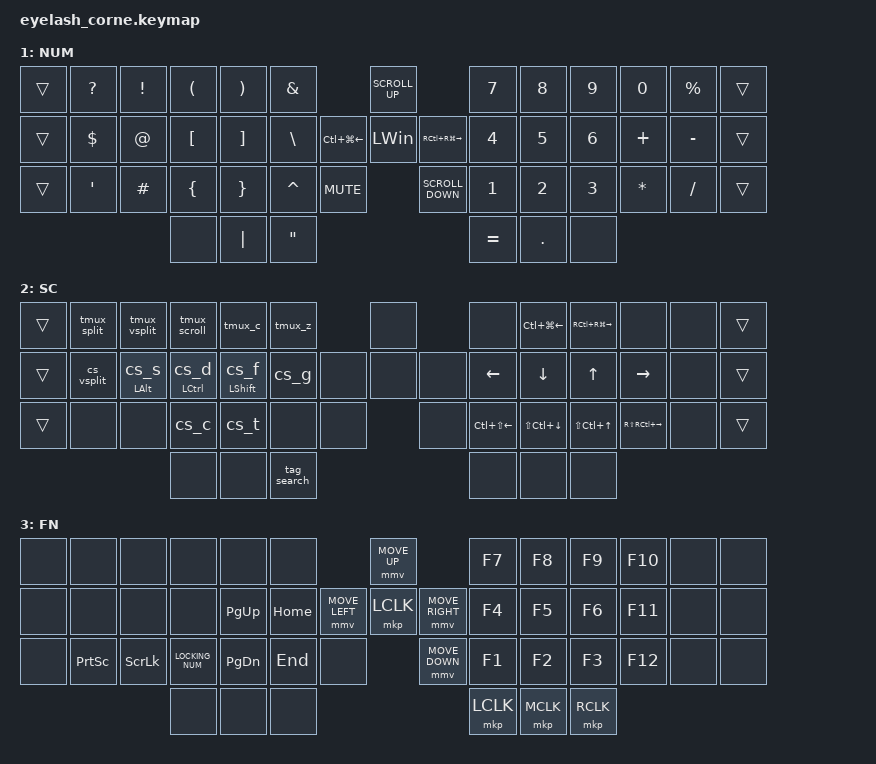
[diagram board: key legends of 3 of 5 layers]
#define ZMK_POINTING_DEFAULT_MOVE_VAL 1200  // 600
#define ZMK_POINTING_DEFAULT_SCRL_VAL 25   // 10
#define MT_TAPPING_TERM_MS 250
#define TD_TAPPING_TERM_MS 200
#define LT_TAPPING_TERM_MS 250
#define TDLT_TD_TAPPING_TERM_MS 185
#define TDLT_TD_TAPPING_TERM_200MS 200
#define TDLT_TD_TAPPING_TERM_175MS 175
#define TDLT_LT_TAPPING_TERM_MS 200
#define TDLT_LT_TAPPING_TERM_225MS 225
#define TDLT_LT_TAPPING_TERM_200MS 200
#define DEFAULT_QUICK_TAP_TERM 200

#include <input/processors.dtsi>
#include <zephyr/dt-bindings/input/input-event-codes.h>
#include <behaviors.dtsi>
#include <dt-bindings/zmk/bt.h>
#include <dt-bindings/zmk/keys.h>
#include <dt-bindings/zmk/pointing.h>
#include <dt-bindings/zmk/rgb.h>

&mmv_input_listener { input-processors = <&zip_xy_scaler 2 1>; };

&msc_input_listener { input-processors = <&zip_scroll_scaler 2 1>; };

&msc {
    acceleration-exponent = <1>;      // 0
    time-to-max-speed-ms = <100>;       // 300
    delay-ms = <0>;                   // 0
};

&led_strip {
    chain-length = <21>; // Or 27 if you have underglow
};

&mmv {
    time-to-max-speed-ms = <500>;
    acceleration-exponent = <1>;
    trigger-period-ms = <16>;
};

&soft_off { hold-time-ms = <2000>; };

/ {
    chosen { zmk,underglow-layer-colors = <&layer_0_color &layer_1_color &layer_2_color &layer_3_color &layer_4_color>; };

    layer_0_color: color_0 {
        color = <0 0 0>; // White for QWERTY Layer
    };

    layer_1_color: color_1 {
        color = <200 100 50>; // Blue for NUM Layer
    };

    layer_2_color: color_2 {
        color = <180 100 50>;   // Cyan for SC Layer
    };

    layer_3_color: color_3 {
        color = <120 100 50>; // Green for FN Layer
    };

    layer_4_color: color_4 {
        color = <0 100 50>; // Red for KBD Layer
    };
};

/ {
    behaviors {
        mt_hp: mt_hp {
            compatible = "zmk,behavior-hold-tap";
            #binding-cells = <2>;
            flavor = "hold-preferred";
            tapping-term-ms = <MT_TAPPING_TERM_MS>;
            quick-tap-ms = <DEFAULT_QUICK_TAP_TERM>;
            bindings = <&kp>, <&kp>;
        };

        mt_tp: mt_tp {
            compatible = "zmk,behavior-hold-tap";
            #binding-cells = <2>;
            flavor = "tap-preferred";
            tapping-term-ms = <MT_TAPPING_TERM_MS>;
            quick-tap-ms = <DEFAULT_QUICK_TAP_TERM>;
            bindings = <&kp>, <&kp>;
        };

        mt_bal: mt_bal {
            compatible = "zmk,behavior-hold-tap";
            #binding-cells = <2>;
            flavor = "balanced";
            tapping-term-ms = <MT_TAPPING_TERM_MS>;
            quick-tap-ms = <DEFAULT_QUICK_TAP_TERM>;
            bindings = <&kp>, <&kp>;
        };

        mt_tui: mt_tui {
            compatible = "zmk,behavior-hold-tap";
            #binding-cells = <2>;
            flavor = "tap-unless-interrupted";
            tapping-term-ms = <MT_TAPPING_TERM_MS>;
            quick-tap-ms = <DEFAULT_QUICK_TAP_TERM>;
            bindings = <&kp>, <&kp>;
        };

        mt_l1_shift_bal: mt_l1_shift_bal {
            compatible = "zmk,behavior-hold-tap";
            #binding-cells = <2>;
            flavor = "balanced";
            tapping-term-ms = <MT_TAPPING_TERM_MS>;
            quick-tap-ms = <DEFAULT_QUICK_TAP_TERM>;
            bindings = <&kp>, <&cs_f>;
        };

        mt_l1_ctrl_bal: mt_l1_ctrl_bal {
            compatible = "zmk,behavior-hold-tap";
            #binding-cells = <2>;
            flavor = "balanced";
            tapping-term-ms = <MT_TAPPING_TERM_MS>;
            quick-tap-ms = <DEFAULT_QUICK_TAP_TERM>;
            bindings = <&kp>, <&cs_d>;
        };

        mt_l1_alt_bal: mt_l1_alt_bal {
            compatible = "zmk,behavior-hold-tap";
            #binding-cells = <2>;
            flavor = "balanced";
            tapping-term-ms = <MT_TAPPING_TERM_MS>;
            quick-tap-ms = <DEFAULT_QUICK_TAP_TERM>;
            bindings = <&kp>, <&cs_s>;
        };

        mt_l1_shift_hp: mt_l1_shift_hp {
            compatible = "zmk,behavior-hold-tap";
            #binding-cells = <2>;
            flavor = "hold-preferred";
            tapping-term-ms = <MT_TAPPING_TERM_MS>;
            quick-tap-ms = <DEFAULT_QUICK_TAP_TERM>;
            bindings = <&kp>, <&cs_f>;
        };

        mt_l1_ctrl_hp: mt_l1_ctrl_hp {
            compatible = "zmk,behavior-hold-tap";
            #binding-cells = <2>;
            flavor = "hold-preferred";
            tapping-term-ms = <MT_TAPPING_TERM_MS>;
            quick-tap-ms = <DEFAULT_QUICK_TAP_TERM>;
            bindings = <&kp>, <&cs_d>;
        };

        mt_l1_alt_hp: mt_l1_alt_hp {
            compatible = "zmk,behavior-hold-tap";
            #binding-cells = <2>;
            flavor = "hold-preferred";
            tapping-term-ms = <MT_TAPPING_TERM_MS>;
            quick-tap-ms = <DEFAULT_QUICK_TAP_TERM>;
            bindings = <&kp>, <&cs_s>;
        };

        mt_l1_shift_tui: mt_l1_shift_tui {
            compatible = "zmk,behavior-hold-tap";
            #binding-cells = <2>;
            flavor = "tap-unless-interrupted";
            tapping-term-ms = <MT_TAPPING_TERM_MS>;
            quick-tap-ms = <DEFAULT_QUICK_TAP_TERM>;
            bindings = <&kp>, <&cs_f>;
        };

        mt_l1_ctrl_tui: mt_l1_ctrl_tui {
            compatible = "zmk,behavior-hold-tap";
            #binding-cells = <2>;
            flavor = "tap-unless-interrupted";
            tapping-term-ms = <MT_TAPPING_TERM_MS>;
            quick-tap-ms = <DEFAULT_QUICK_TAP_TERM>;
            bindings = <&kp>, <&cs_d>;
        };

        mt_l1_alt_tui: mt_l1_alt_tui {
            compatible = "zmk,behavior-hold-tap";
            #binding-cells = <2>;
            flavor = "tap-unless-interrupted";
            tapping-term-ms = <MT_TAPPING_TERM_MS>;
            quick-tap-ms = <DEFAULT_QUICK_TAP_TERM>;
            bindings = <&kp>, <&cs_s>;
        };

        lt_hp: lt_hp {
            compatible = "zmk,behavior-hold-tap";
            #binding-cells = <2>;
            flavor = "hold-preferred";
            tapping-term-ms = <TDLT_LT_TAPPING_TERM_MS>;
            quick-tap-ms = <DEFAULT_QUICK_TAP_TERM>;
            bindings = <&mo>, <&kp>;
        };

        lt_hp_200: lt_hp_200 {
            compatible = "zmk,behavior-hold-tap";
            #binding-cells = <2>;
            flavor = "hold-preferred";
            tapping-term-ms = <TDLT_LT_TAPPING_TERM_200MS>;
            quick-tap-ms = <DEFAULT_QUICK_TAP_TERM>;
            bindings = <&mo>, <&kp>;
        };

        lt_hp_225: lt_hp_225 {
            compatible = "zmk,behavior-hold-tap";
            #binding-cells = <2>;
            flavor = "hold-preferred";
            tapping-term-ms = <TDLT_LT_TAPPING_TERM_225MS>;
            quick-tap-ms = <DEFAULT_QUICK_TAP_TERM>;
            bindings = <&mo>, <&kp>;
        };

        lt_tp: lt_tp {
            compatible = "zmk,behavior-hold-tap";
            #binding-cells = <2>;
            flavor = "tap-preferred";
            tapping-term-ms = <TDLT_LT_TAPPING_TERM_MS>;
            quick-tap-ms = <DEFAULT_QUICK_TAP_TERM>;
            bindings = <&mo>, <&kp>;
        };

        lt_bal: lt_bal {
            compatible = "zmk,behavior-hold-tap";
            #binding-cells = <2>;
            flavor = "balanced";
            tapping-term-ms = <TDLT_LT_TAPPING_TERM_MS>;
            quick-tap-ms = <DEFAULT_QUICK_TAP_TERM>;
            bindings = <&mo>, <&kp>;
        };

        lt_tui: lt_tui {
            compatible = "zmk,behavior-hold-tap";
            #binding-cells = <2>;
            flavor = "tap-unless-interrupted";
            tapping-term-ms = <TDLT_LT_TAPPING_TERM_MS>;
            quick-tap-ms = <DEFAULT_QUICK_TAP_TERM>;
            bindings = <&mo>, <&kp>;
        };

        lt_bal_250_0: lt_bal_250_0 {
            compatible = "zmk,behavior-hold-tap";
            #binding-cells = <2>;
            flavor = "balanced";
            tapping-term-ms = <LT_TAPPING_TERM_MS>;
            quick-tap-ms = <DEFAULT_QUICK_TAP_TERM>;
            bindings = <&mo>, <&kp>;
        };

        lt_bal_250_25: lt_bal_250_25 {
            compatible = "zmk,behavior-hold-tap";
            #binding-cells = <2>;
            flavor = "balanced";
            tapping-term-ms = <LT_TAPPING_TERM_MS>;
            quick-tap-ms = <DEFAULT_QUICK_TAP_TERM>;
            bindings = <&mo>, <&kp>;
        };

        lt_bal_250_25_rgb_L1: lt_bal_250_25_rgb_L1 {
            compatible = "zmk,behavior-hold-tap";
            #binding-cells = <2>;
            flavor = "balanced";
            tapping-term-ms = <LT_TAPPING_TERM_MS>;
            quick-tap-ms = <DEFAULT_QUICK_TAP_TERM>;
            bindings = <&mo_rgb_1>, <&kp>;
        };

        lt_bal_250_25_rgb_L2: lt_bal_250_25_rgb_L2 {
            compatible = "zmk,behavior-hold-tap";
            #binding-cells = <2>;
            flavor = "balanced";
            tapping-term-ms = <LT_TAPPING_TERM_MS>;
            quick-tap-ms = <DEFAULT_QUICK_TAP_TERM>;
            bindings = <&mo_rgb_2>, <&kp>;
        };

        lt_bal_250_25_rgb_L3: lt_bal_250_25_rgb_L3 {
            compatible = "zmk,behavior-hold-tap";
            #binding-cells = <2>;
            flavor = "balanced";
            tapping-term-ms = <LT_TAPPING_TERM_MS>;
            quick-tap-ms = <DEFAULT_QUICK_TAP_TERM>;
            bindings = <&mo_rgb_3>, <&kp>;
        };

        lt_bal_250_25_rgb_L4: lt_bal_250_25_rgb_L4 {
            compatible = "zmk,behavior-hold-tap";
            #binding-cells = <2>;
            flavor = "balanced";
            tapping-term-ms = <LT_TAPPING_TERM_MS>;
            quick-tap-ms = <DEFAULT_QUICK_TAP_TERM>;
            bindings = <&mo_rgb_4>, <&kp>;
        };

        lt_bal_250_50: lt_bal_250_50 {
            compatible = "zmk,behavior-hold-tap";
            #binding-cells = <2>;
            flavor = "balanced";
            tapping-term-ms = <LT_TAPPING_TERM_MS>;
            quick-tap-ms = <DEFAULT_QUICK_TAP_TERM>;
            bindings = <&mo>, <&kp>;
        };

        lt_bal_250_100: lt_bal_250_100 {
            compatible = "zmk,behavior-hold-tap";
            #binding-cells = <2>;
            flavor = "balanced";
            tapping-term-ms = <LT_TAPPING_TERM_MS>;
            quick-tap-ms = <DEFAULT_QUICK_TAP_TERM>;
            bindings = <&mo>, <&kp>;
        };

        lt_tp_250_0: lt_tp_250_0 {
            compatible = "zmk,behavior-hold-tap";
            #binding-cells = <2>;
            flavor = "tap-preferred";
            tapping-term-ms = <LT_TAPPING_TERM_MS>;
            quick-tap-ms = <DEFAULT_QUICK_TAP_TERM>;
            bindings = <&mo>, <&kp>;
        };

        lt_tp_250_50: lt_tp_250_50 {
            compatible = "zmk,behavior-hold-tap";
            #binding-cells = <2>;
            flavor = "tap-preferred";
            tapping-term-ms = <LT_TAPPING_TERM_MS>;
            quick-tap-ms = <DEFAULT_QUICK_TAP_TERM>;
            bindings = <&mo>, <&kp>;
        };

        lt_tui_250_0: lt_tui_250_0 {
            compatible = "zmk,behavior-hold-tap";
            #binding-cells = <2>;
            flavor = "tap-unless-interrupted";
            tapping-term-ms = <LT_TAPPING_TERM_MS>;
            quick-tap-ms = <DEFAULT_QUICK_TAP_TERM>;
            bindings = <&mo>, <&kp>;
        };

        lt_tui_250_50: lt_tui_250_50 {
            compatible = "zmk,behavior-hold-tap";
            #binding-cells = <2>;
            flavor = "tap-unless-interrupted";
            tapping-term-ms = <LT_TAPPING_TERM_MS>;
            quick-tap-ms = <DEFAULT_QUICK_TAP_TERM>;
            bindings = <&mo>, <&kp>;
        };

        td_lt_bal_space_grave_L1: td_lt_bal_space_grave_L1 {
            compatible = "zmk,behavior-tap-dance";
            #binding-cells = <0>;
            tapping-term-ms = <TDLT_TD_TAPPING_TERM_MS>;
            bindings = <&lt_bal 1 SPACE>, <&kp GRAVE>;
        };

        td_lt_bal_enter_esc_L1: td_lt_bal_enter_esc_L1 {
            compatible = "zmk,behavior-tap-dance";
            #binding-cells = <0>;
            tapping-term-ms = <TDLT_TD_TAPPING_TERM_MS>;
            bindings = <&lt_bal 1 RETURN>, <&kp ESC>;
        };

        td_lt_hp_space_grave_L1: td_lt_hp_space_grave_L1 {
            compatible = "zmk,behavior-tap-dance";
            #binding-cells = <0>;
            tapping-term-ms = <TDLT_TD_TAPPING_TERM_MS>;
            bindings = <&lt_hp 1 SPACE>, <&kp GRAVE>;
        };

        td_lt_hp_enter_esc_L1: td_lt_hp_enter_esc_L1 {
            compatible = "zmk,behavior-tap-dance";
            #binding-cells = <0>;
            tapping-term-ms = <TDLT_TD_TAPPING_TERM_MS>;
            bindings = <&lt_hp 1 RETURN>, <&kp ESC>;
        };

        td_200_lt_225_hp_space_grave_L1: td_200_lt_225_hp_space_grave_L1 {
            compatible = "zmk,behavior-tap-dance";
            #binding-cells = <0>;
            tapping-term-ms = <TDLT_TD_TAPPING_TERM_200MS>;
            bindings = <&lt_hp_225 1 SPACE>, <&kp GRAVE>;
        };

        td_200_lt_225_hp_enter_esc_L1: td_200_lt_225_hp_enter_esc_L1 {
            compatible = "zmk,behavior-tap-dance";
            #binding-cells = <0>;
            tapping-term-ms = <TDLT_TD_TAPPING_TERM_200MS>;
            bindings = <&lt_hp_225 1 RETURN>, <&kp ESC>;
        };

        td_200_lt_200_hp_space_grave_L1: td_200_lt_200_hp_space_grave_L1 {
            compatible = "zmk,behavior-tap-dance";
            #binding-cells = <0>;
            tapping-term-ms = <TDLT_TD_TAPPING_TERM_200MS>;
            bindings = <&lt_hp_200 1 SPACE>, <&kp GRAVE>;
        };

        td_200_lt_200_hp_enter_esc_L1: td_200_lt_200_hp_enter_esc_L1 {
            compatible = "zmk,behavior-tap-dance";
            #binding-cells = <0>;
            tapping-term-ms = <TDLT_TD_TAPPING_TERM_200MS>;
            bindings = <&lt_hp_200 1 RETURN>, <&kp ESC>;
        };

        td_175_lt_200_hp_space_grave_L1: td_175_lt_200_hp_space_grave_L1 {
            compatible = "zmk,behavior-tap-dance";
            #binding-cells = <0>;
            tapping-term-ms = <TDLT_TD_TAPPING_TERM_175MS>;
            bindings = <&lt_hp_200 1 SPACE>, <&kp GRAVE>;
        };

        td_175_lt_200_hp_enter_esc_L1: td_175_lt_200_hp_enter_esc_L1 {
            compatible = "zmk,behavior-tap-dance";
            #binding-cells = <0>;
            tapping-term-ms = <TDLT_TD_TAPPING_TERM_175MS>;
            bindings = <&lt_hp_200 1 RETURN>, <&kp ESC>;
        };

        td_lt_tp_space_grave_L1: td_lt_tp_space_grave_L1 {
            compatible = "zmk,behavior-tap-dance";
            #binding-cells = <0>;
            tapping-term-ms = <TDLT_TD_TAPPING_TERM_MS>;
            bindings = <&lt_tp 1 SPACE>, <&kp GRAVE>;
        };

        td_lt_tp_enter_esc_L1: td_lt_tp_enter_esc_L1 {
            compatible = "zmk,behavior-tap-dance";
            #binding-cells = <0>;
            tapping-term-ms = <TDLT_TD_TAPPING_TERM_MS>;
            bindings = <&lt_tp 1 RETURN>, <&kp ESC>;
        };

        td_lt_tui_space_grave_L1: td_lt_tui_space_grave_L1 {
            compatible = "zmk,behavior-tap-dance";
            #binding-cells = <0>;
            tapping-term-ms = <TDLT_TD_TAPPING_TERM_MS>;
            bindings = <&lt_tui 1 SPACE>, <&kp GRAVE>;
        };

        td_lt_tui_enter_esc_L1: td_lt_tui_enter_esc_L1 {
            compatible = "zmk,behavior-tap-dance";
            #binding-cells = <0>;
            tapping-term-ms = <TDLT_TD_TAPPING_TERM_MS>;
            bindings = <&lt_tui 1 RETURN>, <&kp ESC>;
        };

        td_comma_underscore: td_comma_underscore {
            compatible = "zmk,behavior-tap-dance";
            #binding-cells = <0>;
            tapping-term-ms = <TD_TAPPING_TERM_MS>;
            bindings = <&kp COMMA>, <&kp LS(MINUS)>;
        };
    };

    rgb_encoder: rgb_encoder {
        compatible = "zmk,behavior-sensor-rotate";
        #sensor-binding-cells = <0>;
        bindings = <&rgb_ug RGB_BRI>, <&rgb_ug RGB_BRD>;
    };

    scroll_encoder: scroll_encoder {
        compatible = "zmk,behavior-sensor-rotate";
        #sensor-binding-cells = <0>;
        bindings = <&msc SCRL_DOWN>, <&msc SCRL_UP>;

        tap-ms = <100>;
    };

    virtual_win_encoder: virtual_win_encoder {
        compatible = "zmk,behavior-sensor-rotate";
        #sensor-binding-cells = <0>;
        bindings = <&kp LC(LG(LEFT))>, <&kp RC(RG(RIGHT))>;

        tap-ms = <100>;
    };

    tab_scroll_encoder: tab_scroll_encoder {
        compatible = "zmk,behavior-sensor-rotate";
        #sensor-binding-cells = <0>;
        bindings = <&kp LC(TAB)>, <&kp LC(LS(TAB))>;

        tap-ms = <100>;
    };

    vim_undo_redo_encoder: vim_undo_redo_encoder {
        compatible = "zmk,behavior-sensor-rotate";
        #sensor-binding-cells = <0>;
        bindings = <&kp U>, <&kp R>;

        tap-ms = <100>;
    };

    combos {
        compatible = "zmk,combos";

        combo_esc {
            bindings = <&kp ESCAPE>;
            key-positions = <38 39>;
            require-prior-idle-ms = <DEFAULT_QUICK_TAP_TERM>;
            layers = <0>;
            timeout-ms = <50>;
        };

        combo_grave {
            bindings = <&kp GRAVE>;
            key-positions = <9 10>;
            require-prior-idle-ms = <DEFAULT_QUICK_TAP_TERM>;
            layers = <0>;
            timeout-ms = <50>;
        };

        combo_quote {
            bindings = <&kp SINGLE_QUOTE>;
            key-positions = <3 4>;
            timeout-ms = <10>;
            require-prior-idle-ms = <50>;
            layers = <0>;
        };
    };

    macros {
        // Layer 1: Purple

        mo_rgb_1: mo_rgb_1 {
            compatible = "zmk,behavior-macro";
            #binding-cells = <0>;
            wait-ms = <0>;  // Remove delay between commands
            tap-ms = <0>;   // Remove press duration delay
            bindings =
                <&macro_press>,
                <&mo 1>,
                <&macro_tap>,
                <&rgb_ug RGB_ON &rgb_ug RGB_COLOR_HSB(280,100,50)>,
                <&macro_pause_for_release>,
                <&macro_release>,
                <&mo 1>,
                <&macro_tap>,
                <&rgb_ug RGB_OFF>;
        };

        // Layer 2: Green

        mo_rgb_2: mo_rgb_2 {
            compatible = "zmk,behavior-macro";
            #binding-cells = <0>;
            wait-ms = <0>;  // Remove delay between commands
            tap-ms = <0>;   // Remove press duration delay
            bindings =
                <&macro_press>,
                <&mo 2>,
                <&macro_tap>,
                <&rgb_ug RGB_ON &rgb_ug RGB_COLOR_HSB(120,100,50)>,
                <&macro_pause_for_release>,
                <&macro_release>,
                <&mo 2>,
                <&macro_tap>,
                <&rgb_ug RGB_OFF>;
        };

        // Layer 3: Blue

        mo_rgb_3: mo_rgb_3 {
            compatible = "zmk,behavior-macro";
            #binding-cells = <0>;
            wait-ms = <0>;  // Remove delay between commands
            tap-ms = <0>;   // Remove press duration delay
            bindings =
                <&macro_press>,
                <&mo 3>,
                <&macro_tap>,
                <&rgb_ug RGB_ON &rgb_ug RGB_COLOR_HSB(240,100,50)>,
                <&macro_pause_for_release>,
                <&macro_release>,
                <&mo 3>,
                <&macro_tap>,
                <&rgb_ug RGB_OFF>;
        };

        // Layer 4: Red

        mo_rgb_4: mo_rgb_4 {
            compatible = "zmk,behavior-macro";
            #binding-cells = <0>;
            wait-ms = <0>;  // Remove delay between commands
            tap-ms = <0>;   // Remove press duration delay
            bindings =
                <&macro_press>,
                <&mo 4>,
                <&macro_tap>,
                <&rgb_ug RGB_ON &rgb_ug RGB_COLOR_HSB(0,100,50)>,
                <&macro_pause_for_release>,
                <&macro_release>,
                <&mo 4>,
                <&macro_tap>,
                <&rgb_ug RGB_OFF>;
        };

        tmux_h: tmux_h {
            compatible = "zmk,behavior-macro";
            #binding-cells = <0>;
            bindings = <&kp GRAVE &kp H>;
            label = "TMUX_H";
        };

        tmux_j: tmux_j {
            compatible = "zmk,behavior-macro";
            #binding-cells = <0>;
            bindings = <&kp GRAVE &kp J>;
            label = "TMUX_J";
        };

        tmux_k: tmux_k {
            compatible = "zmk,behavior-macro";
            #binding-cells = <0>;
            bindings = <&kp GRAVE &kp K>;
            label = "TMUX_K";
        };

        tmux_l: tmux_l {
            compatible = "zmk,behavior-macro";
            #binding-cells = <0>;
            bindings = <&kp GRAVE &kp L>;
            label = "TMUX_L";
        };

        tmux_c: tmux_c {
            compatible = "zmk,behavior-macro";
            #binding-cells = <0>;
            bindings = <&kp GRAVE &kp C>;
            label = "TMUX_C";
        };

        tmux_scroll: tmux_scroll {
            compatible = "zmk,behavior-macro";
            #binding-cells = <0>;
            bindings = <&kp GRAVE &kp LEFT_BRACKET>;
            label = "TMUX_SCROLL";
        };

        tmux_vsplit: tmux_vsplit {
            compatible = "zmk,behavior-macro";
            #binding-cells = <0>;
            bindings = <&kp GRAVE &kp LS(BACKSLASH)>;
            label = "TMUX_VSPLIT";
        };

        tmux_split: tmux_split {
            compatible = "zmk,behavior-macro";
            #binding-cells = <0>;
            bindings = <&kp GRAVE &kp LS(MINUS)>;
            label = "TMUX_SPLIT";
        };

        cs_g: cs_g {
            compatible = "zmk,behavior-macro";
            #binding-cells = <0>;
            bindings = <&kp LC(BACKSLASH) &kp G>;
            label = "CS_G";
        };

        cs_c: cs_c {
            compatible = "zmk,behavior-macro";
            #binding-cells = <0>;
            bindings = <&kp LC(BACKSLASH) &kp C>;
            label = "CS_C";
        };

        cs_s: cs_s {
            compatible = "zmk,behavior-macro";
            #binding-cells = <0>;
            bindings = <&kp LC(NON_US_BACKSLASH) &kp S>;
            label = "CS_S";
        };

        cs_d: cs_d {
            compatible = "zmk,behavior-macro";
            #binding-cells = <0>;
            bindings = <&kp LC(BACKSLASH) &kp D>;
            label = "CS_D";
        };

        cs_f: cs_f {
            compatible = "zmk,behavior-macro";
            #binding-cells = <0>;
            bindings = <&kp LC(BACKSLASH) &kp F>;
            label = "CS_F";
        };

        cs_t: cs_t {
            compatible = "zmk,behavior-macro";
            #binding-cells = <0>;
            bindings = <&kp LC(BACKSLASH) &kp T>;
            label = "CS_T";
        };

        cs_i: cs_i {
            compatible = "zmk,behavior-macro";
            #binding-cells = <0>;
            bindings = <&kp LC(BACKSLASH) &kp I>;
            label = "CS_I";
        };

        cs_vsplit: cs_vsplit {
            compatible = "zmk,behavior-macro";
            #binding-cells = <0>;
            bindings = <&kp LC(SPACE) &kp LC(SPACE) &kp S>;
            label = "CS_VSPLIT";
            wait-ms = <1>;
            tap-ms = <1>;
        };

        tag_search: tag_search {
            compatible = "zmk,behavior-macro";
            #binding-cells = <0>;
            bindings = <&kp LC(RIGHT_BRACKET)>;
            label = "TAG_SEARCH";
        };

        tmux_z: tmux_z {
            compatible = "zmk,behavior-macro";
            #binding-cells = <0>;
            bindings = <&kp GRAVE &kp Z>;
            label = "TMUX_Z";
        };
    };

    keymap {
        compatible = "zmk,keymap";

        QWERTY {
            display-name = "QWERTY";
            bindings = <
&kp ESC       &kp Q             &kp W              &kp E               &kp R                  &kp T                                &kp UP                &kp Y                  &kp U                  &kp I                  &kp O               &kp P                     &kp GRAVE
&caps_word    &mt_bal DELETE A  &mt_tp LEFT_ALT S  &mt_bal LCTRL D     &mt_bal LEFT_SHIFT F   &kp G                      &kp LEFT  &kp ENTER  &kp RIGHT  &kp H                  &mt_bal RIGHT_SHIFT J  &mt_bal RCTRL K        &mt_tp RIGHT_ALT L  &mt_bal INSERT SEMICOLON  &kp BACKSLASH
&kp LEFT_WIN  &kp Z             &kp X              &kp C               &kp V                  &kp B         &mo_rgb_4              &kp DOWN              &kp N                  &kp M                  &td_comma_underscore   &kp DOT             &kp FSLH                  &lt_bal_250_25_rgb_L4
                                                   &none SINGLE_QUOTE  &lt_bal_250_25_rgb_L3  &none ESCAPE                                               &lt_bal_250_25_rgb_L2  &none BACKSPACE        &lt_bal_250_25_rgb_L1
            >;

            sensor-bindings = <&tab_scroll_encoder>;
        };

        NUM {
            display-name = "NUM";
            bindings = <
&trans  &kp QUESTION      &kp EXCLAMATION  &kp LEFT_PARENTHESIS  &kp RIGHT_PARENTHESIS  &kp AMPERSAND                                            &kp K_SCROLL_UP                       &kp NUMBER_7  &kp NUMBER_8  &kp NUMBER_9  &kp NUMBER_0  &kp PERCENT  &trans
&trans  &kp DOLLAR        &kp AT           &kp LEFT_BRACKET      &kp RIGHT_BRACKET      &kp BACKSLASH                    &kp LC(LG(LEFT_ARROW))  &kp LEFT_WIN       &kp RC(RG(RIGHT))  &kp NUMBER_4  &kp NUMBER_5  &kp NUMBER_6  &kp PLUS      &kp MINUS    &trans
&trans  &kp SINGLE_QUOTE  &kp HASH         &kp LEFT_BRACE        &kp RIGHT_BRACE        &kp CARET          &kp C_MUTE                            &kp K_SCROLL_DOWN                     &kp NUMBER_1  &kp NUMBER_2  &kp NUMBER_3  &kp ASTERISK  &kp SLASH    &trans
                                           &none                 &kp PIPE               &kp DOUBLE_QUOTES                                                                              &kp EQUAL     &kp PERIOD    &none
            >;

            sensor-bindings = <&virtual_win_encoder>;
        };

        SC {
            display-name = "SC";
            bindings = <
&trans  &tmux_split  &tmux_vsplit               &tmux_scroll             &tmux_c                        &tmux_z                      &none         &none             &kp LC(LG(LEFT))  &kp RC(RG(RIGHT))  &none              &none  &trans
&trans  &cs_vsplit   &mt_l1_alt_bal LEFT_ALT 0  &mt_l1_ctrl_bal LCTRL 0  &mt_l1_shift_bal LEFT_SHIFT 0  &cs_g                 &none  &none  &none  &kp LEFT          &kp DOWN          &kp UP_ARROW       &kp RIGHT          &none  &trans
&trans  &none        &none                      &cs_c                    &cs_t                          &none        &none           &none         &kp LC(LS(LEFT))  &kp LS(LC(DOWN))  &kp LS(LC(UP))     &kp RS(RC(RIGHT))  &none  &trans
                                                &none                    &none                          &tag_search                                &none             &none             &none
            >;

            sensor-bindings = <&vim_undo_redo_encoder>;
        };

        FN {
            display-name = "FN";
            bindings = <
&none  &none            &none           &none            &none      &none                              &mmv MOVE_UP                     &kp F7     &kp F8     &kp F9     &kp F10  &none  &none
&none  &none            &none           &none            &kp PG_UP  &kp HOME           &mmv MOVE_LEFT  &mkp LCLK       &mmv MOVE_RIGHT  &kp F4     &kp F5     &kp F6     &kp F11  &none  &none
&none  &kp PRINTSCREEN  &kp SCROLLLOCK  &kp LOCKING_NUM  &kp PG_DN  &kp END   &none                    &mmv MOVE_DOWN                   &kp F1     &kp F2     &kp F3     &kp F12  &none  &none
                                        &none            &none      &none                                                               &mkp LCLK  &mkp MCLK  &mkp RCLK
            >;

            sensor-bindings = <&scroll_encoder>;
        };

        KBD {
            display-name = "KBD";
            bindings = <
&soft_off       &trans  &trans  &trans  &trans  &sys_reset                             &rgb_ug RGB_BRI                   &bt BT_SEL 0                     &bt BT_SEL 1                      &bt BT_SEL 2                      &bt BT_SEL 3                      &bt BT_SEL 4                      &trans
&trans          &trans  &trans  &trans  &trans  &trans                &rgb_ug RGB_EFR  &rgb_ug RGB_TOG  &rgb_ug RGB_EFF  &trans                           &bt BT_NXT                        &bt BT_PRV                        &trans                            &trans                            &bt BT_CLR
&studio_unlock  &trans  &trans  &trans  &trans  &bootloader  &to 0                     &rgb_ug RGB_BRD                   &rgb_ug RGB_COLOR_HSB(55,89,49)  &rgb_ug RGB_COLOR_HSB(117,78,48)  &rgb_ug RGB_COLOR_HSB(182,88,49)  &rgb_ug RGB_COLOR_HSB(240,88,50)  &rgb_ug RGB_COLOR_HSB(344,97,52)  &rgb_ug RGB_COLOR_HSB(271,83,50)
                                &trans  &trans  &trans                                                                   &trans                           &trans                            &trans
            >;

            sensor-bindings = <&rgb_encoder>;
        };
    };
};
